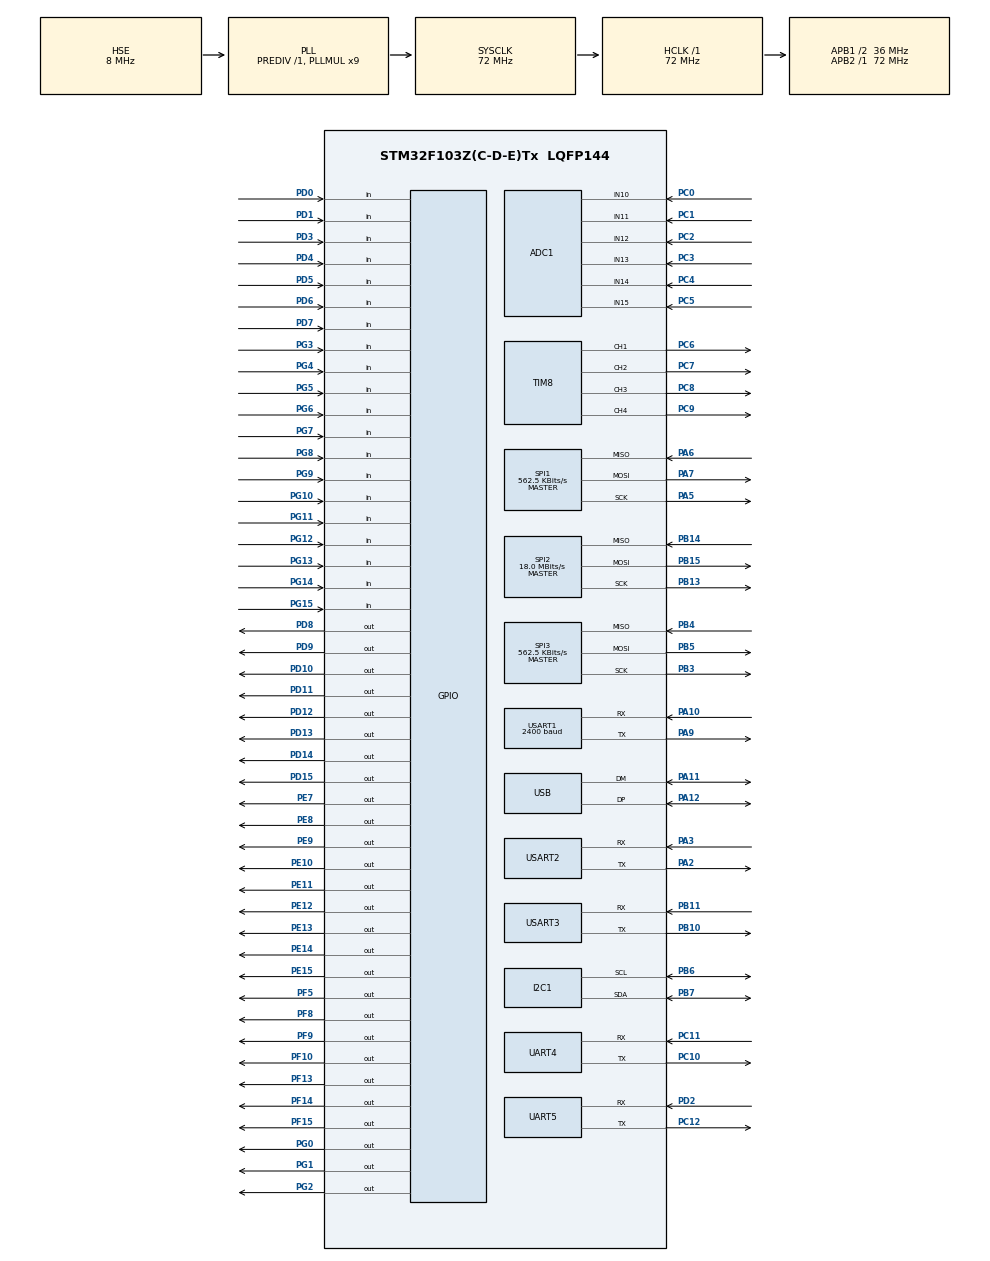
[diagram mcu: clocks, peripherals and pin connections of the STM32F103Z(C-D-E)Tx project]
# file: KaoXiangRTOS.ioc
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ADC1.Channel-1\#ChannelRegularConversion=ADC_CHANNEL_10
ADC1.Channel-2\#ChannelRegularConversion=ADC_CHANNEL_11
ADC1.Channel-3\#ChannelRegularConversion=ADC_CHANNEL_12
ADC1.Channel-4\#ChannelRegularConversion=ADC_CHANNEL_13
ADC1.Channel-5\#ChannelRegularConversion=ADC_CHANNEL_14
ADC1.Channel-6\#ChannelRegularConversion=ADC_CHANNEL_15
ADC1.ContinuousConvMode=ENABLE
ADC1.EnableInjectedConversion=DISABLE
ADC1.InjNumberOfConversion=0
ADC1.NbrOfConversion=6
ADC1.NbrOfConversionFlag=1
ADC1.Rank-1\#ChannelRegularConversion=1
ADC1.Rank-2\#ChannelRegularConversion=2
ADC1.Rank-3\#ChannelRegularConversion=3
ADC1.Rank-4\#ChannelRegularConversion=4
ADC1.Rank-5\#ChannelRegularConversion=5
ADC1.Rank-6\#ChannelRegularConversion=6
ADC1.SamplingTime-1\#ChannelRegularConversion=ADC_SAMPLETIME_1CYCLE_5
ADC1.SamplingTime-2\#ChannelRegularConversion=ADC_SAMPLETIME_1CYCLE_5
ADC1.SamplingTime-3\#ChannelRegularConversion=ADC_SAMPLETIME_1CYCLE_5
ADC1.SamplingTime-4\#ChannelRegularConversion=ADC_SAMPLETIME_1CYCLE_5
ADC1.SamplingTime-5\#ChannelRegularConversion=ADC_SAMPLETIME_1CYCLE_5
ADC1.SamplingTime-6\#ChannelRegularConversion=ADC_SAMPLETIME_1CYCLE_5
ADC1.master=1
Dma.ADC1.3.Direction=DMA_PERIPH_TO_MEMORY
Dma.ADC1.3.Instance=DMA1_Channel1
Dma.ADC1.3.MemDataAlignment=DMA_MDATAALIGN_HALFWORD
Dma.ADC1.3.MemInc=DMA_MINC_ENABLE
Dma.ADC1.3.Mode=DMA_CIRCULAR
Dma.ADC1.3.PeriphDataAlignment=DMA_PDATAALIGN_HALFWORD
Dma.ADC1.3.PeriphInc=DMA_PINC_DISABLE
Dma.ADC1.3.Priority=DMA_PRIORITY_MEDIUM
Dma.Request0=USART2_TX
Dma.Request1=USART2_RX
Dma.Request2=SPI1_RX
Dma.Request3=ADC1
Dma.Request4=USART1_TX
Dma.SPI1_RX.2.Direction=DMA_PERIPH_TO_MEMORY
Dma.SPI1_RX.2.Instance=DMA1_Channel2
Dma.SPI1_RX.2.MemDataAlignment=DMA_MDATAALIGN_BYTE
Dma.SPI1_RX.2.MemInc=DMA_MINC_ENABLE
Dma.SPI1_RX.2.Mode=DMA_NORMAL
Dma.SPI1_RX.2.PeriphDataAlignment=DMA_PDATAALIGN_BYTE
Dma.SPI1_RX.2.PeriphInc=DMA_PINC_DISABLE
Dma.SPI1_RX.2.Priority=DMA_PRIORITY_MEDIUM
Dma.USART1_TX.4.Direction=DMA_MEMORY_TO_PERIPH
Dma.USART1_TX.4.Instance=DMA1_Channel4
Dma.USART1_TX.4.MemDataAlignment=DMA_MDATAALIGN_BYTE
Dma.USART1_TX.4.MemInc=DMA_MINC_ENABLE
Dma.USART1_TX.4.Mode=DMA_NORMAL
Dma.USART1_TX.4.PeriphDataAlignment=DMA_PDATAALIGN_BYTE
Dma.USART1_TX.4.PeriphInc=DMA_PINC_DISABLE
Dma.USART1_TX.4.Priority=DMA_PRIORITY_LOW
Dma.USART2_RX.1.Direction=DMA_PERIPH_TO_MEMORY
Dma.USART2_RX.1.Instance=DMA1_Channel6
Dma.USART2_RX.1.MemDataAlignment=DMA_MDATAALIGN_BYTE
Dma.USART2_RX.1.MemInc=DMA_MINC_ENABLE
Dma.USART2_RX.1.Mode=DMA_CIRCULAR
Dma.USART2_RX.1.PeriphDataAlignment=DMA_PDATAALIGN_BYTE
Dma.USART2_RX.1.PeriphInc=DMA_PINC_DISABLE
Dma.USART2_RX.1.Priority=DMA_PRIORITY_MEDIUM
Dma.USART2_TX.0.Direction=DMA_MEMORY_TO_PERIPH
Dma.USART2_TX.0.Instance=DMA1_Channel7
Dma.USART2_TX.0.MemDataAlignment=DMA_MDATAALIGN_BYTE
Dma.USART2_TX.0.MemInc=DMA_MINC_ENABLE
Dma.USART2_TX.0.Mode=DMA_NORMAL
Dma.USART2_TX.0.PeriphDataAlignment=DMA_PDATAALIGN_BYTE
Dma.USART2_TX.0.PeriphInc=DMA_PINC_DISABLE
Dma.USART2_TX.0.Priority=DMA_PRIORITY_MEDIUM
FREERTOS.HEAP_NUMBER=4
FREERTOS.Queues01=tempQueue,8,OVEN_TempHandleTypeDef,0,Dynamic,NULL,NULL;humiQueue,8,OVEN_HumiHandleTypeDef,0,Dynamic,NULL,NULL;outputQueue,16,uint16_t,0,Dynamic,NULL,NULL
FREERTOS.Tasks01=defaultTask,0,128,StartDefaultTask,Default,NULL,Dynamic,NULL,NULL;ledTask,-3,128,LedTask,Default,NULL,Dynamic,NULL,NULL;usartTask,-3,128,UsartTask,Default,NULL,Dynamic,NULL,NULL;spiTask,-3,128,SpiTask,Default,NULL,Dynamic,NULL,NULL;inputTask,-3,128,InputTask,Default,NULL,Dynamic,NULL,NULL;outputTask,-3,128,OutputTask,Default,NULL,Dynamic,NULL,NULL;adcTask,-3,128,AdcTask,Default,NULL,Dynamic,NULL,NULL;tempTask,-3,128,TempTask,Default,NULL,Dynamic,NULL,NULL;humiTask,-3,128,HumiTask,Default,NULL,Dynamic,NULL,NULL
FREERTOS.configTOTAL_HEAP_SIZE=10240
FREERTOS.configUSE_TIMERS=0
Mcu.Family=STM32F1
Mcu.Name=STM32F103Z(C-D-E)Tx
Mcu.Package=LQFP144
NVIC.ADC1_2_IRQn=true\:5\:0\:false\:false\:true\:true\:true\:true
NVIC.DMA1_Channel1_IRQn=true\:5\:0\:false\:false\:true\:true\:false\:true
NVIC.DMA1_Channel2_IRQn=true\:5\:0\:false\:false\:true\:true\:false\:true
NVIC.DMA1_Channel4_IRQn=true\:5\:0\:false\:false\:true\:true\:false\:true
NVIC.DMA1_Channel6_IRQn=true\:5\:0\:false\:false\:true\:true\:false\:true
NVIC.DMA1_Channel7_IRQn=true\:5\:0\:false\:false\:true\:true\:false\:true
NVIC.PriorityGroup=NVIC_PRIORITYGROUP_4
NVIC.SPI1_IRQn=true\:5\:0\:false\:false\:true\:true\:true\:true
NVIC.TIM6_IRQn=true\:0\:0\:false\:false\:true\:false\:false\:true
NVIC.TimeBase=TIM6_IRQn
NVIC.TimeBaseIP=TIM6
NVIC.USART1_IRQn=true\:5\:0\:false\:false\:true\:true\:true\:true
NVIC.USART2_IRQn=true\:5\:0\:false\:false\:true\:true\:true\:true
OSC_IN.Mode=HSE-External-Oscillator
OSC_IN.Signal=RCC_OSC_IN
OSC_OUT.Mode=HSE-External-Oscillator
OSC_OUT.Signal=RCC_OSC_OUT
PA10.Mode=Asynchronous
PA10.Signal=USART1_RX
PA11.Mode=Device
PA11.Signal=USB_DM
PA12.Mode=Device
PA12.Signal=USB_DP
PA13.Mode=Serial_Wire
PA13.Signal=SYS_JTMS-SWDIO
PA14.Mode=Serial_Wire
PA14.Signal=SYS_JTCK-SWCLK
PA2.Mode=Asynchronous
PA2.Signal=USART2_TX
PA3.Mode=Asynchronous
PA3.Signal=USART2_RX
PA5.Mode=Full_Duplex_Master
PA5.Signal=SPI1_SCK
PA6.Mode=Full_Duplex_Master
PA6.Signal=SPI1_MISO
PA7.Mode=Full_Duplex_Master
PA7.Signal=SPI1_MOSI
PA9.Mode=Asynchronous
PA9.Signal=USART1_TX
PB10.Mode=Asynchronous
PB10.Signal=USART3_TX
PB11.Mode=Asynchronous
PB11.Signal=USART3_RX
PB13.Mode=Full_Duplex_Master
PB13.Signal=SPI2_SCK
PB14.Mode=Full_Duplex_Master
PB14.Signal=SPI2_MISO
PB15.Mode=Full_Duplex_Master
PB15.Signal=SPI2_MOSI
PB3.Mode=Full_Duplex_Master
PB3.Signal=SPI3_SCK
PB4.Mode=Full_Duplex_Master
PB4.Signal=SPI3_MISO
PB5.Mode=Full_Duplex_Master
PB5.Signal=SPI3_MOSI
PB6.Mode=I2C
PB6.Signal=I2C1_SCL
PB7.Mode=I2C
PB7.Signal=I2C1_SDA
PC0.Signal=ADCx_IN10
PC1.Signal=ADCx_IN11
PC10.Mode=Asynchronous
PC10.Signal=UART4_TX
PC11.Mode=Asynchronous
PC11.Signal=UART4_RX
PC12.Mode=Asynchronous
PC12.Signal=UART5_TX
PC2.Signal=ADCx_IN12
PC3.Signal=ADCx_IN13
PC4.Signal=ADCx_IN14
PC5.Signal=ADCx_IN15
PC6.Signal=S_TIM8_CH1
PC7.Signal=S_TIM8_CH2
PC8.Signal=S_TIM8_CH3
PC9.Signal=S_TIM8_CH4
PD0.Signal=GPIO_Input
PD1.Signal=GPIO_Input
PD10.PinState=GPIO_PIN_SET
PD10.Signal=GPIO_Output
PD11.PinState=GPIO_PIN_SET
PD11.Signal=GPIO_Output
PD12.PinState=GPIO_PIN_SET
PD12.Signal=GPIO_Output
PD13.PinState=GPIO_PIN_SET
PD13.Signal=GPIO_Output
PD14.PinState=GPIO_PIN_SET
PD14.Signal=GPIO_Output
PD15.PinState=GPIO_PIN_SET
PD15.Signal=GPIO_Output
PD2.Mode=Asynchronous
PD2.Signal=UART5_RX
PD3.Signal=GPIO_Input
PD4.Signal=GPIO_Input
PD5.Signal=GPIO_Input
PD6.Signal=GPIO_Input
PD7.Signal=GPIO_Input
PD8.PinState=GPIO_PIN_SET
PD8.Signal=GPIO_Output
PD9.PinState=GPIO_PIN_SET
PD9.Signal=GPIO_Output
PE10.PinState=GPIO_PIN_SET
PE10.Signal=GPIO_Output
PE11.PinState=GPIO_PIN_SET
PE11.Signal=GPIO_Output
PE12.PinState=GPIO_PIN_SET
PE12.Signal=GPIO_Output
PE13.PinState=GPIO_PIN_SET
PE13.Signal=GPIO_Output
PE14.PinState=GPIO_PIN_SET
PE14.Signal=GPIO_Output
PE15.PinState=GPIO_PIN_SET
PE15.Signal=GPIO_Output
PE7.PinState=GPIO_PIN_SET
PE7.Signal=GPIO_Output
PE8.PinState=GPIO_PIN_SET
PE8.Signal=GPIO_Output
PE9.PinState=GPIO_PIN_SET
PE9.Signal=GPIO_Output
PF10.Signal=GPIO_Output
PF13.Signal=GPIO_Output
PF14.Signal=GPIO_Output
PF15.Signal=GPIO_Output
PF5.Signal=GPIO_Output
PF8.Signal=GPIO_Output
PF9.Signal=GPIO_Output
PG0.PinState=GPIO_PIN_SET
PG0.Signal=GPIO_Output
PG1.PinState=GPIO_PIN_SET
PG1.Signal=GPIO_Output
PG10.Signal=GPIO_Input
PG11.Signal=GPIO_Input
PG12.Signal=GPIO_Input
PG13.Signal=GPIO_Input
PG14.Signal=GPIO_Input
PG15.Signal=GPIO_Input
PG2.PinState=GPIO_PIN_SET
PG2.Signal=GPIO_Output
PG3.Signal=GPIO_Input
PG4.Signal=GPIO_Input
PG5.Signal=GPIO_Input
PG6.Signal=GPIO_Input
PG7.Signal=GPIO_Input
PG8.Signal=GPIO_Input
PG9.Signal=GPIO_Input
ProjectManager.HeapSize=0x200
ProjectManager.StackSize=0x400
ProjectManager.TargetToolchain=MDK-ARM V5
RCC.ADCPresc=RCC_ADCPCLK2_DIV6
RCC.AHBFreq_Value=72000000
RCC.APB1CLKDivider=RCC_HCLK_DIV2
RCC.APB1Freq_Value=36000000
RCC.APB1TimFreq_Value=72000000
RCC.APB2Freq_Value=72000000
RCC.APB2TimFreq_Value=72000000
RCC.HCLKFreq_Value=72000000
RCC.PLLMUL=RCC_PLL_MUL9
RCC.PLLSourceVirtual=RCC_PLLSOURCE_HSE
RCC.SYSCLKFreq_VALUE=72000000
RCC.SYSCLKSource=RCC_SYSCLKSOURCE_PLLCLK
RCC.USBFreq_Value=48000000
RCC.USBPrescaler=RCC_USBCLKSOURCE_PLL_DIV1_5
SH.ADCx_IN10.0=ADC1_IN10,IN10
SH.ADCx_IN11.0=ADC1_IN11,IN11
SH.ADCx_IN12.0=ADC1_IN12,IN12
SH.ADCx_IN13.0=ADC1_IN13,IN13
SH.ADCx_IN14.0=ADC1_IN14,IN14
SH.ADCx_IN15.0=ADC1_IN15,IN15
SH.S_TIM8_CH1.0=TIM8_CH1,PWM Generation1 CH1
SH.S_TIM8_CH2.0=TIM8_CH2,PWM Generation2 CH2
SH.S_TIM8_CH3.0=TIM8_CH3,PWM Generation3 CH3
SH.S_TIM8_CH4.0=TIM8_CH4,PWM Generation4 CH4
SPI1.BaudRatePrescaler=SPI_BAUDRATEPRESCALER_128
SPI1.CRCCalculation=SPI_CRCCALCULATION_DISABLE
SPI1.CalculateBaudRate=562.5 KBits/s
SPI1.DataSize=SPI_DATASIZE_8BIT
SPI1.Direction=SPI_DIRECTION_2LINES
SPI1.Mode=SPI_MODE_MASTER
SPI1.VirtualType=VM_MASTER
SPI2.CalculateBaudRate=18.0 MBits/s
SPI2.Direction=SPI_DIRECTION_2LINES
SPI2.Mode=SPI_MODE_MASTER
SPI2.VirtualType=VM_MASTER
SPI3.BaudRatePrescaler=SPI_BAUDRATEPRESCALER_64
SPI3.CalculateBaudRate=562.5 KBits/s
SPI3.Direction=SPI_DIRECTION_2LINES
SPI3.Mode=SPI_MODE_MASTER
SPI3.VirtualType=VM_MASTER
TIM8.Channel-PWM\ Generation1\ CH1=TIM_CHANNEL_1
TIM8.Channel-PWM\ Generation2\ CH2=TIM_CHANNEL_2
TIM8.Channel-PWM\ Generation3\ CH3=TIM_CHANNEL_3
TIM8.Channel-PWM\ Generation4\ CH4=TIM_CHANNEL_4
UART4.VirtualMode=Asynchronous
UART5.VirtualMode=Asynchronous
USART1.BaudRate=2400
USART1.VirtualMode=VM_ASYNC
USART2.VirtualMode=VM_ASYNC
USART3.VirtualMode=VM_ASYNC
VP_FREERTOS_VS_CMSIS_V1.Mode=CMSIS_V1
VP_SYS_VS_tim6.Mode=TIM6
VP_TIM2_VS_ClockSourceINT.Mode=Internal
VP_TIM8_VS_ClockSourceINT.Mode=Internal
board=custom

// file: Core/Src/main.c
/* USER CODE BEGIN Header */
/**
  ******************************************************************************
  * @file           : main.c
  * @brief          : Main program body
  ******************************************************************************
  * @attention
  *
  * <h2><center>&copy; Copyright (c) 2022 STMicroelectronics.
  * All rights reserved.</center></h2>
  *
  * This software component is licensed by ST under Ultimate Liberty license
  * SLA0044, the "License"; You may not use this file except in compliance with
  * the License. You may obtain a copy of the License at:
  *                             www.st.com/SLA0044
  *
  ******************************************************************************
  */
/* USER CODE END Header */
#include "main.h"
#include "cmsis_os.h"
#include "adc.h"
#include "dma.h"
#include "i2c.h"
#include "spi.h"
#include "tim.h"
#include "usart.h"
#include "usb.h"
#include "gpio.h"

void SystemClock_Config(void);
void MX_FREERTOS_Init(void);

int main(void)
{

  /* MCU Configuration--------------------------------------------------------*/

  /* Reset of all peripherals, Initializes the Flash interface and the Systick. */
  HAL_Init();

  /* Configure the system clock */
  SystemClock_Config();

  /* Initialize all configured peripherals */
  MX_GPIO_Init();
  MX_DMA_Init();
  MX_TIM2_Init();
  MX_ADC1_Init();
  MX_TIM8_Init();
  MX_USART1_UART_Init();
  MX_USART2_UART_Init();
  MX_I2C1_Init();
  MX_SPI1_Init();
  MX_SPI2_Init();
  MX_SPI3_Init();
  MX_UART4_Init();
  MX_UART5_Init();
  MX_USART3_UART_Init();
  MX_USB_PCD_Init();

  /* Call init function for freertos objects (in freertos.c) */
  MX_FREERTOS_Init();
  /* Start scheduler */
  osKernelStart();

  /* We should never get here as control is now taken by the scheduler */
  /* Infinite loop */
  while (1)
  {

  }
}

void SystemClock_Config(void)
{
  RCC_OscInitTypeDef RCC_OscInitStruct = {0};
  RCC_ClkInitTypeDef RCC_ClkInitStruct = {0};
  RCC_PeriphCLKInitTypeDef PeriphClkInit = {0};

  /** Initializes the RCC Oscillators according to the specified parameters
  * in the RCC_OscInitTypeDef structure.
  */
  RCC_OscInitStruct.OscillatorType = RCC_OSCILLATORTYPE_HSE;
  RCC_OscInitStruct.HSEState = RCC_HSE_ON;
  RCC_OscInitStruct.HSEPredivValue = RCC_HSE_PREDIV_DIV1;
  RCC_OscInitStruct.HSIState = RCC_HSI_ON;
  RCC_OscInitStruct.PLL.PLLState = RCC_PLL_ON;
  RCC_OscInitStruct.PLL.PLLSource = RCC_PLLSOURCE_HSE;
  RCC_OscInitStruct.PLL.PLLMUL = RCC_PLL_MUL9;
  if (HAL_RCC_OscConfig(&RCC_OscInitStruct) != HAL_OK)
  {
    Error_Handler();
  }
  /** Initializes the CPU, AHB and APB buses clocks
  */
  RCC_ClkInitStruct.ClockType = RCC_CLOCKTYPE_HCLK|RCC_CLOCKTYPE_SYSCLK
                              |RCC_CLOCKTYPE_PCLK1|RCC_CLOCKTYPE_PCLK2;
  RCC_ClkInitStruct.SYSCLKSource = RCC_SYSCLKSOURCE_PLLCLK;
  RCC_ClkInitStruct.AHBCLKDivider = RCC_SYSCLK_DIV1;
  RCC_ClkInitStruct.APB1CLKDivider = RCC_HCLK_DIV2;
  RCC_ClkInitStruct.APB2CLKDivider = RCC_HCLK_DIV1;

  if (HAL_RCC_ClockConfig(&RCC_ClkInitStruct, FLASH_LATENCY_2) != HAL_OK)
  {
    Error_Handler();
  }
  PeriphClkInit.PeriphClockSelection = RCC_PERIPHCLK_ADC|RCC_PERIPHCLK_USB;
  PeriphClkInit.AdcClockSelection = RCC_ADCPCLK2_DIV6;
  PeriphClkInit.UsbClockSelection = RCC_USBCLKSOURCE_PLL_DIV1_5;
  if (HAL_RCCEx_PeriphCLKConfig(&PeriphClkInit) != HAL_OK)
  {
    Error_Handler();
  }
}

 /**
  * @brief  Period elapsed callback in non blocking mode
  * @note   This function is called  when TIM6 interrupt took place, inside
  * HAL_TIM_IRQHandler(). It makes a direct call to HAL_IncTick() to increment
  * a global variable "uwTick" used as application time base.
  * @param  htim : TIM handle
  * @retval None
  */
void HAL_TIM_PeriodElapsedCallback(TIM_HandleTypeDef *htim)
{
  if (htim->Instance == TIM6) {
    HAL_IncTick();
  }
}

void Error_Handler(void)
{
  __disable_irq();
  while (1)
  {
  }
}

/************************ (C) COPYRIGHT STMicroelectronics *****END OF FILE****/

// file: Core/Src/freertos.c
/* USER CODE BEGIN Header */
/**
  ******************************************************************************
  * File Name          : freertos.c
  * Description        : Code for freertos applications
  ******************************************************************************
  * @attention
  *
  * <h2><center>&copy; Copyright (c) 2022 STMicroelectronics.
  * All rights reserved.</center></h2>
  *
  * This software component is licensed by ST under Ultimate Liberty license
  * SLA0044, the "License"; You may not use this file except in compliance with
  * the License. You may obtain a copy of the License at:
  *                             www.st.com/SLA0044
  *
  ******************************************************************************
  */
/* USER CODE END Header */

#include "FreeRTOS.h"
#include "task.h"
#include "main.h"
#include "cmsis_os.h"

/* USER CODE BEGIN Includes */
#include <stdio.h>
#include "usart.h"
#include "gpio.h"
#include "spi.h"
#include "adc.h"
#include "queue.h"
/* USER CODE END Includes */

/* USER CODE BEGIN PTD */

typedef struct {

	float							controlTemperature;							//0-1024 'C

	uint8_t						endCondition;

	uint16_t					endTimeSecond;

	uint16_t					endOvenTemperature;

	uint16_t					endCentralTemperature;

} OVEN_TempHandleTypeDef;

typedef struct {

	uint8_t						controlMode;										//steam, spary, steam+spary

	uint8_t						controlHumidity;								//0-10, 0->0%, 1->10%, ..., 10->100%

	uint8_t						endCondition;										//end by time

	uint16_t					endTimeSecond;

} OVEN_HumiHandleTypeDef;

/* USER CODE END PTD */

/* USER CODE BEGIN PD */

//define endCondition
#define END_BY_TIME															00U
#define END_BY_OVEN_TEMPERATURE									01U
#define END_BY_CENTRAL_TEMPERATURE							02U

//define controlMode
#define STEAM_MODE															00U
#define SPRAY_MODE															01U
#define STEAM_SPRAY_MODE												02U

//输出口配置宏定义
#define OUTPUT_OVEN_HEATER											5			//烤箱加热丝输出口
#define OUTPUT_WATER_HEATER											7			//水箱加热丝输出口
#define OUTPUT_OVEN_SPRAY_VALVE									14		//烤箱箱体喷水阀门
#define OUTPUT_STEAM_TANK_VALVE									15		//蒸汽水箱进水阀门
#define OUTPUT_BREATHER_VALVE										16		//烤箱箱体通气阀门

//热电偶配置宏定义
#define TEMP_OVEN_MAIN													0			//烤箱温度计
#define TEMP_STEAM_TANK													1			//水箱温度计

#define WATER_TEMP															95.0	//水箱加热温度

/* USER CODE END PD */

/* USER CODE BEGIN Variables */

uint8_t input_tx_flag;
float spi_temperature[8] = {0};

/* USER CODE END Variables */
osThreadId defaultTaskHandle;
osThreadId ledTaskHandle;
osThreadId usartTaskHandle;
osThreadId spiTaskHandle;
osThreadId inputTaskHandle;
osThreadId outputTaskHandle;
osThreadId adcTaskHandle;
osThreadId tempTaskHandle;
osThreadId humiTaskHandle;
osMessageQId tempQueueHandle;
osMessageQId humiQueueHandle;
osMessageQId outputQueueHandle;

void StartDefaultTask(void const * argument);
void LedTask(void const * argument);
void UsartTask(void const * argument);
void SpiTask(void const * argument);
void InputTask(void const * argument);
void OutputTask(void const * argument);
void AdcTask(void const * argument);
void TempTask(void const * argument);
void HumiTask(void const * argument);

void MX_FREERTOS_Init(void); /* (MISRA C 2004 rule 8.1) */

/* GetIdleTaskMemory prototype (linked to static allocation support) */
void vApplicationGetIdleTaskMemory( StaticTask_t **ppxIdleTaskTCBBuffer, StackType_t **ppxIdleTaskStackBuffer, uint32_t *pulIdleTaskStackSize );

/* USER CODE BEGIN GET_IDLE_TASK_MEMORY */
static StaticTask_t xIdleTaskTCBBuffer;
static StackType_t xIdleStack[configMINIMAL_STACK_SIZE];

void vApplicationGetIdleTaskMemory( StaticTask_t **ppxIdleTaskTCBBuffer, StackType_t **ppxIdleTaskStackBuffer, uint32_t *pulIdleTaskStackSize )
{
  *ppxIdleTaskTCBBuffer = &xIdleTaskTCBBuffer;
  *ppxIdleTaskStackBuffer = &xIdleStack[0];
  *pulIdleTaskStackSize = configMINIMAL_STACK_SIZE;
  /* place for user code */
}
/* USER CODE END GET_IDLE_TASK_MEMORY */

void MX_FREERTOS_Init(void) {

  /* Create the queue(s) */
  /* definition and creation of tempQueue */
  osMessageQDef(tempQueue, 8, OVEN_TempHandleTypeDef);
  tempQueueHandle = osMessageCreate(osMessageQ(tempQueue), NULL);

  /* definition and creation of humiQueue */
  osMessageQDef(humiQueue, 8, OVEN_HumiHandleTypeDef);
  humiQueueHandle = osMessageCreate(osMessageQ(humiQueue), NULL);

  /* definition and creation of outputQueue */
  osMessageQDef(outputQueue, 16, uint16_t);
  outputQueueHandle = osMessageCreate(osMessageQ(outputQueue), NULL);

  /* Create the thread(s) */
  /* definition and creation of defaultTask */
  osThreadDef(defaultTask, StartDefaultTask, osPriorityNormal, 0, 128);
  defaultTaskHandle = osThreadCreate(osThread(defaultTask), NULL);

  /* definition and creation of ledTask */
  osThreadDef(ledTask, LedTask, osPriorityIdle, 0, 128);
  ledTaskHandle = osThreadCreate(osThread(ledTask), NULL);

  /* definition and creation of usartTask */
  osThreadDef(usartTask, UsartTask, osPriorityIdle, 0, 128);
  usartTaskHandle = osThreadCreate(osThread(usartTask), NULL);

  /* definition and creation of spiTask */
  osThreadDef(spiTask, SpiTask, osPriorityIdle, 0, 128);
  spiTaskHandle = osThreadCreate(osThread(spiTask), NULL);

  /* definition and creation of inputTask */
  osThreadDef(inputTask, InputTask, osPriorityIdle, 0, 128);
  inputTaskHandle = osThreadCreate(osThread(inputTask), NULL);

  /* definition and creation of outputTask */
  osThreadDef(outputTask, OutputTask, osPriorityIdle, 0, 128);
  outputTaskHandle = osThreadCreate(osThread(outputTask), NULL);

  /* definition and creation of adcTask */
  osThreadDef(adcTask, AdcTask, osPriorityIdle, 0, 128);
  adcTaskHandle = osThreadCreate(osThread(adcTask), NULL);

  /* definition and creation of tempTask */
  osThreadDef(tempTask, TempTask, osPriorityIdle, 0, 128);
  tempTaskHandle = osThreadCreate(osThread(tempTask), NULL);

  /* definition and creation of humiTask */
  osThreadDef(humiTask, HumiTask, osPriorityIdle, 0, 128);
  humiTaskHandle = osThreadCreate(osThread(humiTask), NULL);

}

void StartDefaultTask(void const * argument)
{
  for(;;)
  {
    osDelay(1);
  }
}

void LedTask(void const * argument)
{
  /* USER CODE BEGIN LedTask */
  /* Infinite loop */
  for(;;)
  {
		HAL_GPIO_TogglePin(GPIOF, GPIO_PIN_13);
    osDelay(1000);
  }
  /* USER CODE END LedTask */
}

void UsartTask(void const * argument)
{
  /* USER CODE BEGIN UsartTask */

	OVEN_TempHandleTypeDef usart_ovenTemperatureHandle;
	OVEN_HumiHandleTypeDef usart_ovenHumidityHandle;

	uint8_t data_head1;
	uint8_t data_head2;
	uint8_t data_address;
	uint8_t data_length;
	uint8_t data_event;
	uint8_t data_checksum;
	uint8_t data_tail1;
	uint8_t data_tail2;
	uint8_t data_rx_err;

	UART_BSP_INIT();

  /* Infinite loop */
  for(;;)
	{

		//1.receive data, check data format

		data_checksum = 0;
		data_rx_err = 0;

		data_head1 = UART2_GET_DATA();
		data_head2 = UART2_GET_DATA();
		if(data_head1 != RX_DATA_HEAD1 || data_head2 != RX_DATA_HEAD2)		//head err
		{
			data_rx_err = 1;
		}
		else		//head ok
		{
			data_address = UART2_GET_DATA();
			if(data_address != RX_DATA_ADDRESS)		//address err
			{
				data_rx_err = 1;
			}
			else		//address ok
			{
				//get data length , event and detail data
				data_length = UART2_GET_DATA();
				data_event = UART2_GET_DATA();
				data_checksum += data_length;
				data_checksum += data_event;
				for(uint8_t i = 0; i < data_length; i++)
				{
					G_RX_BUFF_HANDLE[i] = UART2_GET_DATA();
					data_checksum += G_RX_BUFF_HANDLE[i];
				}
				if(data_checksum != UART2_GET_DATA())		//checksum err
				{
					data_rx_err = 1;
				}
				else		//checksum ok
				{
					data_tail1 = UART2_GET_DATA();
					data_tail2 = UART2_GET_DATA();
					if(data_tail1 != RX_DATA_TAIL1 || data_tail2 != RX_DATA_TAIL2)		//tail err
					{
						data_rx_err = 1;
					}
					else		//tail ok
					{
						HAL_GPIO_TogglePin(GPIOF, GPIO_PIN_14);		//Communication complete, Toggle LED

						G_UART2_TXBUFFER[0] = data_event;
						for(uint8_t i = 0; i < data_length; i++)
						{
							G_UART2_TXBUFFER[0] = G_RX_BUFF_HANDLE[i];
						}
					}
				}
			}
		}

		//2.if data_rx_err == 0(no err), then check data_event(things to do) and get G_RX_BUFF_HANDLE(data)

		if(data_rx_err == 0)
		{
			switch (data_event)
			{

				//test gpio
				case 0x70:
				{
					HAL_GPIO_TogglePin(GPIOF, GPIO_PIN_15);
				}break;

				//test motor
				case 0x71:
				{
					MOTOR_CONTROL(MOTOR_ENABLE, MOTOR_DIR_CW, 0x0700);
					osDelay(5000);
					MOTOR_CONTROL(MOTOR_ENABLE, MOTOR_DIR_CW, 0x0600);
					osDelay(5000);
					MOTOR_CONTROL(MOTOR_ENABLE, MOTOR_DIR_CW, 0x0500);
					osDelay(5000);
					MOTOR_CONTROL(MOTOR_ENABLE, MOTOR_DIR_CW, 0x0400);
					osDelay(5000);
					MOTOR_CONTROL(MOTOR_ENABLE, MOTOR_DIR_CW, 0x0300);
					osDelay(5000);
					MOTOR_CONTROL(MOTOR_DISABLE, MOTOR_DIR_CW, 0x0100);
					osDelay(5000);
					//speed 100-300 is same?
				}break;

				//start transmit input status
				case 0x72:
				{
					input_tx_flag = 1;
				}break;

				//stop transmit input status
				case 0x73:
				{
					input_tx_flag = 0;
				}break;

				//control output
				case 0x74:
				{
					uint8_t output_num = G_RX_BUFF_HANDLE[0];
					uint8_t output_status = G_RX_BUFF_HANDLE[1];
					if(output_status == 1)
					{
						GPIO_OUTPUT_OPEN(output_num);
					}
					else if(output_status == 0)
					{
						GPIO_OUTPUT_CLOSE(output_num);
					}
				}break;

				//tempeature control
				case 0x75:
				{

					uint16_t tempeature = G_RX_BUFF_HANDLE[0] << 8 | G_RX_BUFF_HANDLE[1];
					usart_ovenTemperatureHandle.controlTemperature = ( float ) tempeature;
					usart_ovenTemperatureHandle.endCondition = G_RX_BUFF_HANDLE[2];
					switch (usart_ovenTemperatureHandle.endCondition)
					{
						case END_BY_TIME:
						{
							usart_ovenTemperatureHandle.endTimeSecond = G_RX_BUFF_HANDLE[3] << 8 | G_RX_BUFF_HANDLE[4];
						}break;
						case END_BY_OVEN_TEMPERATURE:
						{
							usart_ovenTemperatureHandle.endOvenTemperature = G_RX_BUFF_HANDLE[3] << 8 | G_RX_BUFF_HANDLE[4];
						}break;
						case END_BY_CENTRAL_TEMPERATURE:
						{
							usart_ovenTemperatureHandle.endCentralTemperature = G_RX_BUFF_HANDLE[3] << 8 | G_RX_BUFF_HANDLE[4];
						}break;
					}

					xQueueSend(tempQueueHandle, ( void * ) &usart_ovenTemperatureHandle, ( TickType_t ) 0);
					printf("tempeature queue send finish.\n");

				}break;

				//humidity control
				case 0x76:
				{

					usart_ovenHumidityHandle.controlMode = G_RX_BUFF_HANDLE[0];
					usart_ovenHumidityHandle.controlHumidity = G_RX_BUFF_HANDLE[1];
					usart_ovenHumidityHandle.endCondition = G_RX_BUFF_HANDLE[2];
					switch (usart_ovenHumidityHandle.endCondition)
					{
						case END_BY_TIME:
						{
							usart_ovenHumidityHandle.endTimeSecond = G_RX_BUFF_HANDLE[3] << 8 | G_RX_BUFF_HANDLE[4];
						}break;
					}

					xQueueSend(humiQueueHandle, ( void * ) &usart_ovenHumidityHandle, ( TickType_t ) 0);
					printf("humidity queue send finish.\n");

				}break;

				//end control
				case 0x77:
				{
					osDelay(200);
					printf("end, open motor and air valve.\n");
					GPIO_OUTPUT_OPEN(OUTPUT_BREATHER_VALVE);
					MOTOR_CONTROL(MOTOR_ENABLE, MOTOR_DIR_CW, 0x0600);
					osDelay(30000);
					GPIO_OUTPUT_CLOSE(OUTPUT_BREATHER_VALVE);
					MOTOR_CONTROL(MOTOR_DISABLE, MOTOR_DIR_CW, 0x0100);
					printf("end.\n");
				}break;

				//suspend all
				case 0x78:
				{
					printf("now suspend output task.\n");
					GPIO_OUTPUT_CLOSEALL();
					MOTOR_CONTROL(MOTOR_DISABLE, MOTOR_DIR_CW, 0x0100);
					vTaskSuspend( tempTaskHandle );
					vTaskSuspend( humiTaskHandle );
				}break;

				//resume all
				case 0x79:
				{
					printf("now resume output task.\n");
					vTaskResume( tempTaskHandle );
					vTaskResume( humiTaskHandle );
				}break;

				//open check
				case 0x80:
				{
					printf("now check open.\n");
					if(spi_temperature[0] == (float) 4096.0)
					{
						printf("cannot find T1, please check\n");
					}
					if(spi_temperature[1] == (float) 4096.0)
					{
						printf("cannot find T2, please check\n");
					}
					//打开进水阀
					GPIO_OUTPUT_OPEN(OUTPUT_STEAM_TANK_VALVE);
					while(1)
					{
						if(!GPIO_INPUT(1))
						{
							osDelay(10);
							if(!GPIO_INPUT(1))
							{
								GPIO_OUTPUT_CLOSE(OUTPUT_STEAM_TANK_VALVE);
								break;
							}
						}
						osDelay(50);
					}
				}break;

			}
		}

		osDelay(10);
  }
  /* USER CODE END UsartTask */
}

void SpiTask(void const * argument)
{
  /* USER CODE BEGIN SpiTask */

	uint16_t max6675_data[8] = {0};

  /* Infinite loop */
  for(;;)
  {
		for(uint8_t i = 0; i < 8; i++)
		{
			max6675_data[i] = SPI_MAX6675(i+1);
			if(max6675_data[i] & 0x04)	//检测不到热电偶
			{
				spi_temperature[i] = (float) 4096.0;
			}
			else
			{
				spi_temperature[i] = (float) (((max6675_data[i] >> 3) & ~(0xF << 12)) * 0.25f);
			}
			osDelay(50);
		}
		if(input_tx_flag == 1)
		{
			printf("spi_temperature:%f,  %f,  %f\n", spi_temperature[0], spi_temperature[1], spi_temperature[2]);
		}
    osDelay(100);
  }
  /* USER CODE END SpiTask */
}

void InputTask(void const * argument)
{
  /* USER CODE BEGIN InputTask */

	uint8_t input_data[20] = {0};

  /* Infinite loop */
  for(;;)
  {
		for(uint8_t i = 0; i < 20; i++)
		{
			input_data[i] = GPIO_INPUT(i+1);
		}
		// if(input_tx_flag == 1)
		// {
		// 	printf("gpio: %u%u%u%u%u %u%u%u%u%u %u%u%u%u%u %u%u%u%u%u\n", input_data[0], input_data[1], input_data[2], input_data[3], input_data[4],
		// 																																input_data[5], input_data[6], input_data[7], input_data[8], input_data[9],
		// 																																input_data[10],input_data[11],input_data[12],input_data[13],input_data[14],
		// 																																input_data[15],input_data[16],input_data[17],input_data[18],input_data[19]);
		// }
    osDelay(1000);
  }
  /* USER CODE END InputTask */
}

void OutputTask(void const * argument)
{
  /* USER CODE BEGIN OutputTask */
	uint8_t status = 0;
  /* Infinite loop */
  for(;;)
  {
		if(!GPIO_INPUT(2) && status == 0)
		{
			printf("now suspend output task.\n");
			GPIO_OUTPUT_CLOSEALL();
			MOTOR_CONTROL(MOTOR_DISABLE, MOTOR_DIR_CW, 0x0100);
			vTaskSuspend( tempTaskHandle );
			vTaskSuspend( humiTaskHandle );
			status = 1;
		}
		else if(GPIO_INPUT(2) && status == 1)
		{
			printf("now resume output task.\n");
			vTaskResume( tempTaskHandle );
			vTaskResume( humiTaskHandle );
			status = 0;
		}

		osDelay(100);
  }
  /* USER CODE END OutputTask */
}

void AdcTask(void const * argument)
{
  /* USER CODE BEGIN AdcTask */

	uint32_t adc_data[3];
	if (HAL_ADC_Start_DMA(&hadc1, (uint32_t *)adc_data, 6) != HAL_OK)
  {
    Error_Handler();
  }

  /* Infinite loop */
  for(;;)
  {
    osDelay(1);
  }
  /* USER CODE END AdcTask */
}

void TempTask(void const * argument)
{
  /* USER CODE BEGIN TempTask */

	uint8_t temp_control_queue_flag = 0;
	uint8_t temp_end_flag = 0;
	uint32_t temp_time_counts;
	uint8_t temp_motor_counts;
	uint16_t temp_motor_speed;
	uint8_t temp_motor_status;
	uint8_t moshi;

	OVEN_TempHandleTypeDef temp_ovenTemperatureHandle;

  /* Infinite loop */
  for(;;)
  {
		//接收队列消息
		if(tempQueueHandle != NULL)
		{
      if( xQueueReceive( tempQueueHandle,
                         &( temp_ovenTemperatureHandle ),
                         ( TickType_t ) 10 ) == pdPASS )
      {
				temp_control_queue_flag = 1;
      }
		}

		//若接收到了队列消息，则开始控制
		if(temp_control_queue_flag == 1)
		{
			temp_time_counts = 0;
			temp_motor_status = 0;
			temp_motor_speed = 0x0700;
			temp_motor_counts = 0;
			switch (temp_ovenTemperatureHandle.endCondition)
			{
				case END_BY_TIME:
				{
					osDelay(200);
					printf("Control temperatrue is: %f\n", temp_ovenTemperatureHandle.controlTemperature);
					osDelay(200);
					printf("End by time,start controling...\n");
					osDelay(200);
					for(temp_time_counts = 0; temp_time_counts < temp_ovenTemperatureHandle.endTimeSecond; temp_time_counts++)
					{
						//temperature control
						if(spi_temperature[TEMP_OVEN_MAIN] < temp_ovenTemperatureHandle.controlTemperature)
						{
							GPIO_OUTPUT_OPEN(OUTPUT_OVEN_HEATER);
						}
						else
						{
							GPIO_OUTPUT_CLOSE(OUTPUT_OVEN_HEATER);
						}
						printf("Current temperature is: %.2f, %.2f, %.2f.\n", spi_temperature[TEMP_OVEN_MAIN], spi_temperature[TEMP_STEAM_TANK], spi_temperature[2]);
						//motor control

						//1.motor speed
						//风机控制模式，1代表蒸的时候风机减速的模式
						//2代表风机正常烤的时候不减速的模式
						moshi = 1;
						temp_motor_speed = 0x0600;

						if(moshi == 1)
						{
							if((temp_time_counts % 615) < 255)
							{
								temp_motor_speed = 0x600;
							}
							if(255 <= (temp_time_counts % 615) && (temp_time_counts % 615) < 315)
							{
								temp_motor_speed = 0x600;
							}
							else if(315 <= (temp_time_counts % 615) && (temp_time_counts % 615) < 375)
							{
								temp_motor_speed = 0x500;
							}
							else if(375 <= (temp_time_counts % 615) && (temp_time_counts % 615) < 435)
							{
								temp_motor_speed = 0x400;
							}
							else if(435 <= (temp_time_counts % 615) && (temp_time_counts % 615) < 495)
							{
								temp_motor_speed = 0x300;
							}
							else if(495 <= (temp_time_counts % 615) && (temp_time_counts % 615) < 615)
							{
								temp_motor_speed = 0x200;
							}
						}
						else if(moshi == 2)
						{
								temp_motor_speed = 0x600;
						}

						//2.motor direction
						if(temp_motor_status == 0)
						{
							if(temp_motor_counts < 112)
							{
								MOTOR_CONTROL(MOTOR_ENABLE, MOTOR_DIR_CW, temp_motor_speed);
								temp_motor_counts++;
							}
							else
							{
								MOTOR_CONTROL(MOTOR_ENABLE, MOTOR_DIR_CW, temp_motor_speed);
								temp_motor_status = 1;
								temp_motor_counts = 0;
							}
						}
						else if(temp_motor_status == 1)
						{
							if(temp_motor_counts < 6)
							{
								MOTOR_CONTROL(MOTOR_DISABLE, MOTOR_DIR_CCW, 0x0100);
								temp_motor_counts++;
							}
							else
							{
								MOTOR_CONTROL(MOTOR_DISABLE, MOTOR_DIR_CCW, 0x0100);
								temp_motor_status = 2;
								temp_motor_counts = 0;
							}
						}
						else if(temp_motor_status == 2)
						{
							if(temp_motor_counts < 112)
							{
								MOTOR_CONTROL(MOTOR_ENABLE, MOTOR_DIR_CCW, temp_motor_speed);
								temp_motor_counts++;
							}
							else
							{
								MOTOR_CONTROL(MOTOR_ENABLE, MOTOR_DIR_CCW, temp_motor_speed);
								temp_motor_status = 3;
								temp_motor_counts = 0;
							}
						}
						else if(temp_motor_status == 3)
						{
							if(temp_motor_counts < 6)
							{
								MOTOR_CONTROL(MOTOR_DISABLE, MOTOR_DIR_CW, 0x0100);
								temp_motor_counts++;
							}
							else
							{
								MOTOR_CONTROL(MOTOR_DISABLE, MOTOR_DIR_CW, 0x0100);
								temp_motor_status = 0;
								temp_motor_counts = 0;
							}
						}
						osDelay(1000);
					}
					GPIO_OUTPUT_CLOSE(OUTPUT_OVEN_HEATER);
					MOTOR_CONTROL(MOTOR_DISABLE, MOTOR_DIR_CW, 0x0100);
					temp_control_queue_flag = 0;
					printf("Temperature control end.\n");
				}break;

				//预热
				case END_BY_OVEN_TEMPERATURE:
				{
					temp_end_flag = 0;
					osDelay(200);
					printf("Control temperatrue is: %f\n", temp_ovenTemperatureHandle.controlTemperature);
					osDelay(200);
					printf("End by oven teamperature,start controling...\n");
					osDelay(200);
					//打开风机
					MOTOR_CONTROL(MOTOR_ENABLE, MOTOR_DIR_CW, 0x0700);
					osDelay(3000);
					//喷水
					GPIO_OUTPUT_OPEN(OUTPUT_OVEN_SPRAY_VALVE);
					osDelay(1000);
					GPIO_OUTPUT_CLOSE(OUTPUT_OVEN_SPRAY_VALVE);
					osDelay(1000);
					//开始加热烤箱
					while(temp_end_flag == 0)
					{
						MOTOR_CONTROL(MOTOR_ENABLE, MOTOR_DIR_CW, 0x0700);
						if(spi_temperature[TEMP_OVEN_MAIN] >= temp_ovenTemperatureHandle.controlTemperature - 30.0)
						{
							osDelay(50);
							printf("1Current temperature is: %f.\n", spi_temperature[TEMP_OVEN_MAIN]);
							GPIO_OUTPUT_OPEN(OUTPUT_OVEN_HEATER);
							osDelay(950);
							if(spi_temperature[TEMP_OVEN_MAIN] >= temp_ovenTemperatureHandle.controlTemperature - 30.0)
							{
								osDelay(50);
								printf("2Current temperature is: %f.\n", spi_temperature[TEMP_OVEN_MAIN]);
								GPIO_OUTPUT_CLOSE(OUTPUT_OVEN_HEATER);
								temp_end_flag = 1;
							}
						}
						else
						{
							osDelay(50);
							printf("Current temperature is: %f.\n", spi_temperature[TEMP_OVEN_MAIN]);
							GPIO_OUTPUT_OPEN(OUTPUT_OVEN_HEATER);
							osDelay(950);
						}
					}
					osDelay(50);
					printf("Temperature control end.\n");
					GPIO_OUTPUT_CLOSE(OUTPUT_OVEN_HEATER);
					//开始加热水箱
					osDelay(200);
					printf("Preheat water,start controling...\n");
					osDelay(200);
					while(spi_temperature[TEMP_STEAM_TANK] < WATER_TEMP)
					{
						printf("Current water temperature is: %f.\n", spi_temperature[TEMP_STEAM_TANK]);
						MOTOR_CONTROL(MOTOR_ENABLE, MOTOR_DIR_CW, 0x0700);
						GPIO_OUTPUT_OPEN(OUTPUT_WATER_HEATER);
						osDelay(1000);
					}
					osDelay(200);
					printf("Preheat water control end.\n");

					//预热结束
					GPIO_OUTPUT_CLOSE(OUTPUT_OVEN_HEATER);
					GPIO_OUTPUT_CLOSE(OUTPUT_WATER_HEATER);
					MOTOR_CONTROL(MOTOR_DISABLE, MOTOR_DIR_CW, 0x0100);
					temp_control_queue_flag = 0;
				}break;

			}

		}
    osDelay(1);
  }
  /* USER CODE END TempTask */
}

void HumiTask(void const * argument)
{
  /* USER CODE BEGIN HumiTask */

	uint32_t humi_time_counts;
	uint8_t humi_control_queue_flag = 0;
	uint8_t humi_pwm_count = 0;
	OVEN_HumiHandleTypeDef humi_ovenHumidityHandle;

  /* Infinite loop */
  for(;;)
  {

		if(humiQueueHandle != NULL)
		{
      if( xQueueReceive( humiQueueHandle,
                         &( humi_ovenHumidityHandle ),
                         ( TickType_t ) 10 ) == pdPASS )
      {
				humi_control_queue_flag = 1;
      }
		}

		if(humi_control_queue_flag == 1)
		{
			humi_time_counts = 0;

			switch (humi_ovenHumidityHandle.controlMode)
			{

				case STEAM_MODE:
				{
					osDelay(200);
					printf("steam mode,start controling...\n");
					osDelay(200);
					for(humi_time_counts = 0; humi_time_counts < humi_ovenHumidityHandle.endTimeSecond; humi_time_counts++)
					{
						if(spi_temperature[TEMP_STEAM_TANK] < WATER_TEMP)
						{
							GPIO_OUTPUT_OPEN(OUTPUT_WATER_HEATER);
						}
						else
						{
							GPIO_OUTPUT_CLOSE(OUTPUT_WATER_HEATER);
						}
						printf("Current steam temperature is: %f.\n", spi_temperature[TEMP_STEAM_TANK]);
						osDelay(1000);
					}
					printf("Humidity control end.\n");
					GPIO_OUTPUT_CLOSE(OUTPUT_WATER_HEATER);
					humi_control_queue_flag = 0;
				}break;

				case SPRAY_MODE:
				{
					osDelay(200);
					printf("Control humidity is: %d\n", humi_ovenHumidityHandle.controlHumidity);
					osDelay(200);
					printf("spray mode,start controling...\n");
					osDelay(200);
					humi_pwm_count = 20 - humi_ovenHumidityHandle.controlHumidity;
					if(humi_pwm_count == 0) humi_pwm_count = 1;
					for(humi_time_counts = 0; humi_time_counts < humi_ovenHumidityHandle.endTimeSecond; humi_time_counts++)
					{
						//若湿度为10（100%），则每隔10秒喷0.75秒水；湿度为1（10%），则每隔19秒喷0.75秒水
						if(humi_time_counts % humi_pwm_count == 0)
						{
							GPIO_OUTPUT_OPEN(OUTPUT_OVEN_SPRAY_VALVE);
							osDelay(750);
							GPIO_OUTPUT_CLOSE(OUTPUT_OVEN_SPRAY_VALVE);
							osDelay(250);
						}
						else
						{
							GPIO_OUTPUT_CLOSE(OUTPUT_OVEN_SPRAY_VALVE);
							osDelay(1000);
						}
					}
					printf("Humidity control end.\n");
					GPIO_OUTPUT_CLOSE(OUTPUT_OVEN_SPRAY_VALVE);
					humi_control_queue_flag = 0;
				}break;

				case STEAM_SPRAY_MODE:
				{
					osDelay(200);
					printf("Control humidity is: %d\n", humi_ovenHumidityHandle.controlHumidity);
					osDelay(200);
					printf("steam spray mode,start controling...\n");
					osDelay(200);
					humi_control_queue_flag = 0;
					for(humi_time_counts = 0; humi_time_counts < humi_ovenHumidityHandle.endTimeSecond; humi_time_counts++)
					{
						//加热蒸汽水箱
						if(spi_temperature[TEMP_STEAM_TANK] < WATER_TEMP)
						{
							GPIO_OUTPUT_OPEN(OUTPUT_WATER_HEATER);
						}
						else
						{
							GPIO_OUTPUT_CLOSE(OUTPUT_WATER_HEATER);
						}
						printf("Current steam temperature is: %f.\n", spi_temperature[TEMP_STEAM_TANK]);

						//烤箱内喷水
						humi_pwm_count = 0;
						//若湿度为10（100%），则每隔10秒喷0.5秒水；湿度为1（10%），则每隔19秒喷0.5秒水
						if(humi_pwm_count < 20 - humi_ovenHumidityHandle.controlHumidity)
						{
							GPIO_OUTPUT_CLOSE(OUTPUT_OVEN_SPRAY_VALVE);
							humi_pwm_count ++;
							osDelay(1000);
						}
						else
						{
							GPIO_OUTPUT_OPEN(OUTPUT_OVEN_SPRAY_VALVE);
							osDelay(500);
							GPIO_OUTPUT_CLOSE(OUTPUT_OVEN_SPRAY_VALVE);
							osDelay(500);
							humi_pwm_count = 0;
						}
					}
					printf("Humidity control end.\n");
					GPIO_OUTPUT_CLOSE(OUTPUT_WATER_HEATER);
					GPIO_OUTPUT_CLOSE(OUTPUT_OVEN_SPRAY_VALVE);
					humi_control_queue_flag = 0;
				}break;
			}
		}
    osDelay(1);
  }
  /* USER CODE END HumiTask */
}

/************************ (C) COPYRIGHT STMicroelectronics *****END OF FILE****/
